# CC2756 register map
File version: 1.0
CPU: CM4 r0p4, little endian, no MPU, no FPU, VTOR, 3 interrupt priority bits
Registers are 32-bit, read-write, reset 0x0 unless marked. A register's access mark holds for its fields unless they carry their own. Offsets are from the block's base; [hi:lo] are bit positions; lines under a group give offsets from that group; {n}, {i} and the like mark numbered series.

## VIMS — Versatile Instruction Memory System Controls memory access to the Flash and encapsulates the following instruction memories: - Boot ROM - Caches
Base 0x40024000
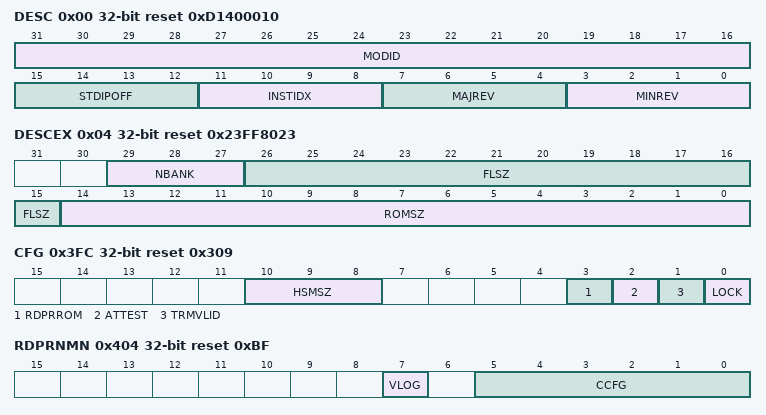
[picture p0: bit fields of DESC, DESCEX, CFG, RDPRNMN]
0x00 DESC ro reset 0xD1400010 — Description Register. This register provides IP module ID, revision information, instance index and standard MMR registers offset.
  [31:16] MODID — Module identification contains a unique peripheral identification number.
  [15:12] STDIPOFF — Standard IP MMR block offset. Standard IP MMRs are the set of from aggregated IRQ registers till DTB. 0: Standard IP MMRs do not exist 0x1-0xF: Standard IP MMRs begin at offset of (64*STDIPOFF from the base IP address)
  [11:8] INSTIDX — IP Instance ID number. If multiple instances of IP exist in the device, this field can identify the instance number (0-15).
  [7:4] MAJREV — Major revision of IP
  [3:0] MINREV — Minor revision of IP
0x04 DESCEX ro reset 0x23FF8023 — Extended Description Register.This register describes the configuration of VIMS.
  [29:27] NBANK — Number of Flash banks
  [26:15] FLSZ — FLASH size in Kilo Bytes. The total FLASH size is (FLSZ + 1) KB
  [14:0] ROMSZ — ROM size in Kilo Bytes. The total ROM size is (ROMSZ + 1) KB
0x08 FLWS1T reset 0xF — Flash Wait State 1T. This register is used to specify the number of waitstates necessary for accessing the flash in 1T mode.
  [3:0] VAL — Flash read wait states for 1T accesses
    {v}=WS{v} (Wait state value {v}) (v=0..15)
0x0C FLWS2T reset 0xF — Flash Wait State 1T. This register is used to specify the number of waitstates necessary for accessing the flash in 2T mode. This register is writable only when CFG.LOCK is 1
  [3:0] VAL — Flash read wait states for 2T accesses
    {v}=WS{v} (Wait state value {v}) (v=0..15)
0x18 PTRMC0 reset 0x131A0000 — FLASH Pump trim Bank 0. This register stores different PUMP trims. This register is writable only when CFG.LOCK is 1
  [31:0] VAL — Flash charge pump trim value.
{0x1C+8i} B{i}TRMC1 (i=0..3) — FLASH Bank {i} Trim [59:32]. This register stores different bank trims. This register is writable only when CFG.LOCK is 1
  [27:0] VAL — Flash bank trim value.
{0x20+8i} B{i}TRMC0 (i=0..3) — FLASH Bank {i} Trim [31:0]. This register stores different bank trims. This register is writable only when CFG.LOCK is 1
  [31:0] VAL — Flash bank trim value.
0x100 FLBLCK — Flash Block. This register is used to block user read, write and erase operation to flash. This register is sticky 1 and writable only when CFG.LOCK is 1
  [0] ACCESS — Flash Access
    1=BLOCK; 0=ALLOW
0x3FC CFG reset 0x309 — Configuration Register. This register is used for VIMS configuration. This register is writable only when CFG.LOCK is 1
  [10:8] HSMSZ — HSM Size. Valid Configuration for HSMSZ is 64KiB, 96KiB and 112KiB.
    7=SIZE_112 (112KB); 6=SIZE_96 (96KB); 4=SIZE_64 (64KB)
  [3] RDPRROM — ROM Read Protection Disable
    1=DIS (Disable); 0=EN (Enable)
  [2] ATTEST — This bit is used to enable flash test mode.
    1=EN (Enable); 0=DIS (Disable)
  [1] TRMVLID — TRIM Valid. This bit indicates if flash charge pump and bank trim values are as applicable.
    1=VLID (Valid); 0=INVLID (Invalid)
  [0] LOCK — Lock. Lock VIMS configuration. This bit is sticky '0' and when 0 write protects following registers FLWS1T FLWS2T PTRMC0 B0TRMC1 B0TRMC0 B1TRMC1 B1TRMC0 B2TRMC1 B2TRMC0 B3TRMC1 B3TRMC0 FLBLCK CFG
    1=DIS (Configuration registers are open for writing); 0=EN (Configuration registers are locked for writing)
0x400 RDPRMN reset 0xF — Read Protect Main. First 16KB of flash main region can be protected with granularity of 2KB. This register is sticky 0
  [3:0] VAL — Protection configuration value. Undefined values will read protect whole protectable region
    15=PROT_0KB (Protection is Disabled); 14=PROT_2KB (Protect First 2KB); 13=PROT_4KB (Protect First 4KB); 12=PROT_6KB (Protect First 6KB); 11=PROT_8KB (Protect First 8KB); 10=PROT_10KB (Protect First 10KB); 9=PROT_12KB (Protect First 12KB); 8=PROT_14KB (Protect First 14KB); 7=PROT_16KB (Protect First 16KB)
0x404 RDPRNMN reset 0xBF — Read Protect Non-Main regions.
  [7] VLOG — VLOG read protection configuration. This field is sticky 0
  [5:0] CCFG — CCFG read protection configuration. Last 512 bytes of CCFG can be protected with granularity of 16Bytes. This field is sticky 0
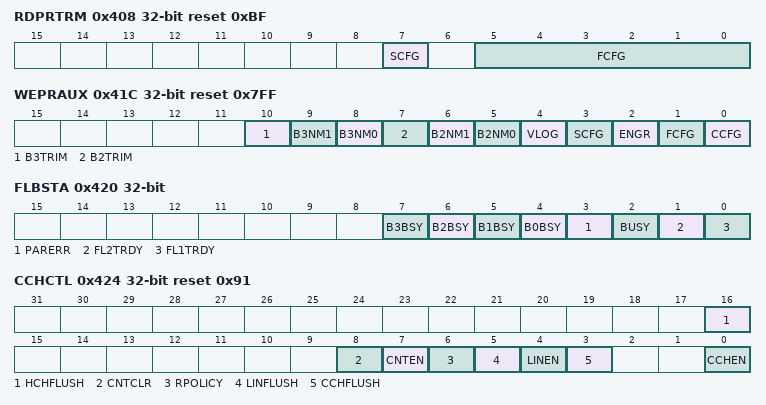
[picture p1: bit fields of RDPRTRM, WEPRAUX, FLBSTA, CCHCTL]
0x408 RDPRTRM reset 0xBF — Read Protect Trim
  [7] SCFG — SCFG read protection configuration. This field is sticky 0
  [5:0] FCFG — FCFG read protection configuration. Last 512 bytes of FCFG can be protected with granularity of 16Bytes. This register is sticky 0
0x40C RDPREGR reset 0x1 — Read Protect ENGR. This register is sticky 0
  [0] ENGR — ENGR read protection configuration.
0x410 WEPRA reset 0xFFFFFFFF — Write Erase Protect Main A. This register allows the first 32 sectors of the logical bank 0 main region to be protected from program or erase, with 1 bit protecting each sector (sector 0 to sector 31). This register is sticky 0
  [31:0] VAL — Flash write/erase protection configuration value.
0x414 WEPRB0 reset 0xFFFFFFFF — Write Erase Protect Main Bank 0. This register allows physical bank 0 main region sectors to be protected from program and erase. Each bit corresponds to a group of 8 sectors. First 4-bit are reserved if physical Bank 0 is logical bank 0 CTL.SWAP = 0. This register is sticky 0
  [31:0] VAL — Flash write/erase protection configuration value.
0x418 WEPRB1 reset 0xFFFFFFFF — Write Erase Protect Main Bank 1. This register allows physical bank 1 main region sectors to be protected from program and erase. Each bit corresponds to a group of 8 sectors. First 4-bit are reserved if physical Bank 1 is logical bank 0 CTL.SWAP = 1. This register is sticky 0
  [31:0] VAL — Flash write/erase protection configuration value.
0x41C WEPRAUX reset 0x7FF — Write Erase Protect Auxillary. Flash Write/Erase protection for Non-Main, TRIM and ENGR Regions. This register is sticky 0
  [10] B3TRIM — Write/Erase Protection for B3TRIM
  [9] B3NM1 — Write/Erase Protection for B3NM1
  [8] B3NM0 — Write/Erase Protection for B3NM0
  [7] B2TRIM — Write/Erase Protection for B2TRIM
  [6] B2NM1 — Write/Erase Protection for B2NM1
  [5] B2NM0 — Write/Erase Protection for B2NM0
  [4] VLOG — Write/Erase Protection for VLOG
  [3] SCFG — Write/Erase Protection for SCFG
  [2] ENGR — Write/Erase Protection for ENGR
  [1] FCFG — Write/Erase Protection for FCFG
  [0] CCFG — Write/Erase Protection for CCFG
0x420 FLBSTA ro — Flash Status. This register is used to indicate status of flash.
  [n+4] B{n}BSY (n=0..3) — Bank {n} Busy. This bit indicates if flash Bank {n} is busy.
    1=BUSY; 0=IDLE
  [3] PARERR — Parity Error. This bit indicates parity error on write/erase $amp; read protection MMRs. This bit is sticky when set to 1 by hardware.
    1=ERR (Error); 0=NOERR (No Error)
  [2] BUSY — This bit indicates if flash is busy.
    1=BUSY; 0=IDLE
  [1] FL2TRDY — Flash 2T Ready. This bit indicates if flash is ready in 2T mode.
    1=RDY (Ready); 0=NOTRDY (Not Ready)
  [0] FL1TRDY — Flash 1T Ready. This bit indicates if flash is ready in 1T mode.
    1=RDY (Ready); 0=NOTRDY (Not Ready)
0x424 CCHCTL reset 0x91 — Cache Control Register. This register is used for cache control on code bus Interface. This register can only be written when CCHSTA.BUSY is 0
  [16] HCHFLUSH wo — Cache Flush for HSM Cache. This bit is used to flush the cache on HSM bus Interface. This bit is self clearing
    1=TRG (Trigger Flush)
  [8] CNTCLR wo — Cache Hit/Miss Count Clear. Writing 0 to this bit has no affect
    1=CLR (Clear Hit/Miss Counter)
  [7] CNTEN — Cache Hit/Miss Count Enable.
    1=EN (Enable); 0=DIS (Disable)
  [6] RPOLICY — Replacement policy for Cache.
    1=SEQ (Sequencial Replacement Policy); 0=RND (Random Replacement Policy)
  [5] LINFLUSH wo — Line Buffer Flush. This bit is used to flush the Line buffer on system bus Interface. Writing 0 to this bit has no affect. The guideline to use the flush: 1. Write CCHCTL.LINFLUSH = 1 (Will flush the SAHB cache) 2. Write CCHCTL.LINFLUSH = 0 (Forcing to disable the Flush)
    1=TRG (Trigger Flush)
  [4] LINEN — Line Buffer Enable. This bit is used to enable the Line buffer on system bus Interface. Disabling the Line buffer will flush it
    1=EN (Enable); 0=DIS (Disable)
  [3] CCHFLUSH wo — Cache Flush. This bit is used to flush the cache on code bus Interface. This bit is self clearing. Writing 0 to this bit has no affect
    1=TRG (Trigger Flush)
  [0] CCHEN — Cache Enable. This bit is used to enable the cache. Disabling the cache will flush it
    1=EN (Enable); 0=DIS (Disable)
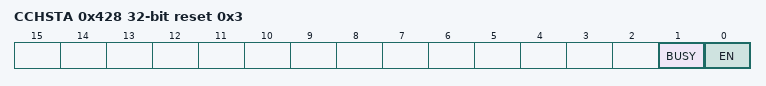
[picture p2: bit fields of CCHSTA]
0x428 CCHSTA ro reset 0x3 — Cache Status. This register gives cache status
  [1] BUSY — Busy. This bit indicate Cache is changing state
    1=BUSY; 0=NBUSY (Not Busy)
  [0] EN — Enabled. This bit indicate whether cache is enabled or disabled
    1=EN (Enabled); 0=DIS (Disabled)
0x430 CNTHIT ro — Cache Hit Counter
  [31:0] VAL — Hit Counter Value. This counter is cleared by writing CCHCTL.CNTCLR
0x434 CNTMISS ro — Cache Miss Counter
  [31:0] VAL — Miss Counter Value. This counter is cleared by writing CCHCTL.CNTCLR
0x438 WEPRB2 reset 0xFFFFFFFF — Write Erase Protect Main Bank 2. This register allows physical bank 2 main region sectors to be protected from program and erase. Each bit corresponds to a group of 8 sectors.
  [31:0] VAL — Flash write/erase protection configuration value.
0x43C WEPRB3 reset 0xFFFFFFFF — Write Erase Protect Main Bank 3. This register allows physical bank 3 main region sectors to be protected from program and erase. Each bit corresponds to a group of 8 sectors.
  [31:0] VAL — Flash write/erase protection configuration value.
0x800 DTB — Digital test bus control register. This register can be used to bring out IP internal signals to the pads for observation. 16 signals can be observed per select value.
  [3:0] SEL — Digital test bus selection mux control. Non-zero select values output a 16 bit selected group of signals per value.
    0=DIS (DTB output from peripheral is 0x0)
